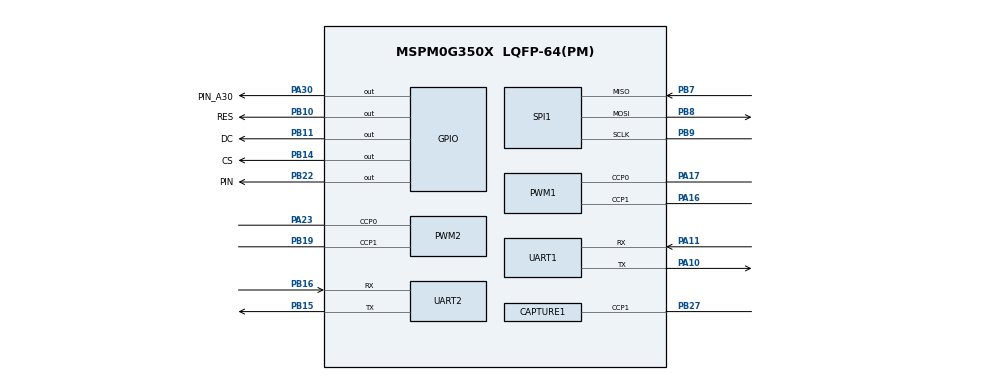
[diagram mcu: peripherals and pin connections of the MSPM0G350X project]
/**
 * @cliArgs --device "MSPM0G350X" --part "Default" --package "LQFP-64(PM)" --product "mspm0_sdk@2.05.01.01"
 * @versions {"tool":"1.21.0+3721"}
 */

/**
 * Import the modules used in this configuration.
 */
const ADC12    = scripting.addModule("/ti/driverlib/ADC12", {}, false);
const ADC121   = ADC12.addInstance();
const CAPTURE  = scripting.addModule("/ti/driverlib/CAPTURE", {}, false);
const CAPTURE1 = CAPTURE.addInstance();
const GPIO     = scripting.addModule("/ti/driverlib/GPIO", {}, false);
const GPIO1    = GPIO.addInstance();
const GPIO2    = GPIO.addInstance();
const GPIO3    = GPIO.addInstance();
const GPIO4    = GPIO.addInstance();
const GPIO5    = GPIO.addInstance();
const GPIO6    = GPIO.addInstance();
const GPIO7    = GPIO.addInstance();
const GPIO8    = GPIO.addInstance();
const GPIO9    = GPIO.addInstance();
const I2C      = scripting.addModule("/ti/driverlib/I2C", {}, false);
const I2C1     = I2C.addInstance();
const PWM      = scripting.addModule("/ti/driverlib/PWM", {}, false);
const PWM1     = PWM.addInstance();
const PWM2     = PWM.addInstance();
const SPI      = scripting.addModule("/ti/driverlib/SPI", {}, false);
const SPI1     = SPI.addInstance();
const SYSCTL   = scripting.addModule("/ti/driverlib/SYSCTL");
const SYSTICK  = scripting.addModule("/ti/driverlib/SYSTICK");
const TIMER    = scripting.addModule("/ti/driverlib/TIMER", {}, false);
const TIMER1   = TIMER.addInstance();
const TIMER2   = TIMER.addInstance();
const TIMER3   = TIMER.addInstance();
const UART     = scripting.addModule("/ti/driverlib/UART", {}, false);
const UART1    = UART.addInstance();
const UART2    = UART.addInstance();

/**
 * Write custom configuration values to the imported modules.
 */
const divider9       = system.clockTree["UDIV"];
divider9.divideValue = 2;

const mux4       = system.clockTree["EXHFMUX"];
mux4.inputSelect = "EXHFMUX_XTAL";

const mux8       = system.clockTree["HSCLKMUX"];
mux8.inputSelect = "HSCLKMUX_SYSPLL2X";

const mux12       = system.clockTree["SYSPLLMUX"];
mux12.inputSelect = "zSYSPLLMUX_HFCLK";

const pinFunction4        = system.clockTree["HFXT"];
pinFunction4.enable       = true;
pinFunction4.HFCLKMonitor = true;
pinFunction4.HFXTStartup  = 20;
pinFunction4.inputFreq    = 40;

ADC121.$name               = "ADC1";
ADC121.sampClkDiv          = "DL_ADC12_CLOCK_DIVIDE_8";
ADC121.repeatMode          = true;
ADC121.startAdd            = 4;
ADC121.adcMem4chansel      = "DL_ADC12_INPUT_CHAN_4";
ADC121.powerDownMode       = "DL_ADC12_POWER_DOWN_MODE_MANUAL";
ADC121.peripheral.$assign  = "ADC1";
ADC121.adcPin4Config.$name = "ti_driverlib_gpio_GPIOPinGeneric10";

const Board = scripting.addModule("/ti/driverlib/Board", {}, false);

CAPTURE1.$name                      = "hongwai";
CAPTURE1.captMode                   = "COMBINED_UP";
CAPTURE1.timerStartTimer            = true;
CAPTURE1.ccIndex                    = 1;
CAPTURE1.interrupts                 = ["CC0_UP","CC1_UP"];
CAPTURE1.timerPeriod                = "30ms";
CAPTURE1.timerClkPrescale           = 200;
CAPTURE1.peripheral.$assign         = "TIMG6";
CAPTURE1.peripheral.ccp1Pin.$assign = "PB27";
CAPTURE1.ccp1PinConfig.$name        = "ti_driverlib_gpio_GPIOPinGeneric7";

GPIO1.$name                          = "LED";
GPIO1.associatedPins[0].$name        = "PIN";
GPIO1.associatedPins[0].ioStructure  = "SD";
GPIO1.associatedPins[0].assignedPort = "PORTB";
GPIO1.associatedPins[0].assignedPin  = "22";
GPIO1.associatedPins[0].pin.$assign  = "PB22";

GPIO2.$name                         = "OLED";
GPIO2.port                          = "PORTB";
GPIO2.associatedPins.create(3);
GPIO2.associatedPins[0].$name       = "RES";
GPIO2.associatedPins[0].ioStructure = "SD";
GPIO2.associatedPins[0].assignedPin = "10";
GPIO2.associatedPins[0].pin.$assign = "PB10";
GPIO2.associatedPins[1].$name       = "DC";
GPIO2.associatedPins[1].ioStructure = "SD";
GPIO2.associatedPins[1].assignedPin = "11";
GPIO2.associatedPins[1].pin.$assign = "PB11";
GPIO2.associatedPins[2].$name       = "CS";
GPIO2.associatedPins[2].ioStructure = "SD";
GPIO2.associatedPins[2].assignedPin = "14";
GPIO2.associatedPins[2].pin.$assign = "PB14";

GPIO3.$name                          = "TB6612";
GPIO3.port                           = "PORTA";
GPIO3.associatedPins.create(4);
GPIO3.associatedPins[0].$name        = "AIN1";
GPIO3.associatedPins[0].initialValue = "SET";
GPIO3.associatedPins[0].assignedPin  = "14";
GPIO3.associatedPins[1].$name        = "AIN2";
GPIO3.associatedPins[1].initialValue = "SET";
GPIO3.associatedPins[1].assignedPin  = "15";
GPIO3.associatedPins[2].$name        = "BIN1";
GPIO3.associatedPins[2].initialValue = "SET";
GPIO3.associatedPins[2].assignedPin  = "12";
GPIO3.associatedPins[3].$name        = "BIN2";
GPIO3.associatedPins[3].initialValue = "SET";
GPIO3.associatedPins[3].assignedPin  = "13";

GPIO4.$name                               = "ENCODER";
GPIO4.port                                = "PORTA";
GPIO4.associatedPins.create(4);
GPIO4.associatedPins[0].$name             = "E1A";
GPIO4.associatedPins[0].direction         = "INPUT";
GPIO4.associatedPins[0].assignedPin       = "27";
GPIO4.associatedPins[0].interruptEn       = true;
GPIO4.associatedPins[0].interruptPriority = "0";
GPIO4.associatedPins[0].polarity          = "RISE";
GPIO4.associatedPins[1].$name             = "E1B";
GPIO4.associatedPins[1].direction         = "INPUT";
GPIO4.associatedPins[1].assignedPin       = "26";
GPIO4.associatedPins[1].interruptEn       = true;
GPIO4.associatedPins[1].interruptPriority = "0";
GPIO4.associatedPins[1].polarity          = "RISE";
GPIO4.associatedPins[2].$name             = "E2A";
GPIO4.associatedPins[2].direction         = "INPUT";
GPIO4.associatedPins[2].assignedPin       = "31";
GPIO4.associatedPins[2].interruptEn       = true;
GPIO4.associatedPins[2].interruptPriority = "0";
GPIO4.associatedPins[2].polarity          = "RISE";
GPIO4.associatedPins[3].$name             = "E2B";
GPIO4.associatedPins[3].direction         = "INPUT";
GPIO4.associatedPins[3].assignedPin       = "28";
GPIO4.associatedPins[3].interruptEn       = true;
GPIO4.associatedPins[3].polarity          = "RISE";
GPIO4.associatedPins[3].interruptPriority = "0";

GPIO5.$name                          = "SR04";
GPIO5.port                           = "PORTB";
GPIO5.associatedPins[0].$name        = "Trig";
GPIO5.associatedPins[0].initialValue = "SET";
GPIO5.associatedPins[0].assignedPin  = "23";

GPIO6.$name                          = "LORA";
GPIO6.associatedPins.create(2);
GPIO6.associatedPins[0].$name        = "PIN_MDO";
GPIO6.associatedPins[0].assignedPort = "PORTB";
GPIO6.associatedPins[0].assignedPin  = "26";
GPIO6.associatedPins[1].$name        = "PIN_AUX";
GPIO6.associatedPins[1].direction    = "INPUT";
GPIO6.associatedPins[1].assignedPort = "PORTA";
GPIO6.associatedPins[1].assignedPin  = "29";

GPIO7.$name                              = "KEY";
GPIO7.associatedPins.create(4);
GPIO7.associatedPins[0].$name            = "key_B25";
GPIO7.associatedPins[0].initialValue     = "SET";
GPIO7.associatedPins[0].assignedPort     = "PORTB";
GPIO7.associatedPins[0].assignedPin      = "25";
GPIO7.associatedPins[0].direction        = "INPUT";
GPIO7.associatedPins[1].$name            = "key_B24";
GPIO7.associatedPins[1].initialValue     = "SET";
GPIO7.associatedPins[1].assignedPort     = "PORTB";
GPIO7.associatedPins[1].assignedPin      = "24";
GPIO7.associatedPins[1].direction        = "INPUT";
GPIO7.associatedPins[1].internalResistor = "PULL_UP";
GPIO7.associatedPins[2].$name            = "key_A24";
GPIO7.associatedPins[2].assignedPort     = "PORTA";
GPIO7.associatedPins[2].assignedPin      = "24";
GPIO7.associatedPins[2].initialValue     = "SET";
GPIO7.associatedPins[2].direction        = "INPUT";
GPIO7.associatedPins[2].internalResistor = "PULL_UP";
GPIO7.associatedPins[3].$name            = "key_A25";
GPIO7.associatedPins[3].initialValue     = "SET";
GPIO7.associatedPins[3].assignedPort     = "PORTA";
GPIO7.associatedPins[3].assignedPin      = "25";
GPIO7.associatedPins[3].direction        = "INPUT";
GPIO7.associatedPins[3].internalResistor = "PULL_UP";

GPIO8.$name                         = "Gray_Address";
GPIO8.port                          = "PORTB";
GPIO8.associatedPins.create(3);
GPIO8.associatedPins[0].$name       = "PIN_0";
GPIO8.associatedPins[0].assignedPin = "18";
GPIO8.associatedPins[1].$name       = "PIN_1";
GPIO8.associatedPins[1].assignedPin = "0";
GPIO8.associatedPins[2].$name       = "PIN_2";
GPIO8.associatedPins[2].assignedPin = "20";

GPIO9.$name                         = "ZIsedeng";
GPIO9.port                          = "PORTA";
GPIO9.associatedPins[0].$name       = "PIN_A30";
GPIO9.associatedPins[0].assignedPin = "30";
GPIO9.associatedPins[0].pin.$assign = "PA30";

I2C1.$name                 = "I2C_0";
I2C1.basicEnableController = true;
I2C1.sdaPinConfig.$name    = "ti_driverlib_gpio_GPIOPinGeneric8";
I2C1.sclPinConfig.$name    = "ti_driverlib_gpio_GPIOPinGeneric9";

PWM1.$name                      = "PWM_0";
PWM1.timerStartTimer            = true;
PWM1.clockDivider               = 8;
PWM1.timerCount                 = 8000;
PWM1.peripheral.ccp0Pin.$assign = "PA17";
PWM1.peripheral.ccp1Pin.$assign = "PA16";
PWM1.PWM_CHANNEL_0.$name        = "ti_driverlib_pwm_PWMTimerCC0";
PWM1.PWM_CHANNEL_0.invert       = true;
PWM1.PWM_CHANNEL_1.$name        = "ti_driverlib_pwm_PWMTimerCC1";
PWM1.PWM_CHANNEL_1.invert       = true;
PWM1.ccp0PinConfig.$name        = "ti_driverlib_gpio_GPIOPinGeneric5";
PWM1.ccp1PinConfig.$name        = "ti_driverlib_gpio_GPIOPinGeneric6";

PWM2.$name                              = "PWM_Servo";
PWM2.clockDivider                       = 8;
PWM2.timerStartTimer                    = true;
PWM2.clockPrescale                      = 20;
PWM2.timerCount                         = 10000;
PWM2.peripheral.ccp0Pin.$assign         = "PA23";
PWM2.peripheral.ccp1Pin.$assign         = "PB19";
PWM2.PWM_CHANNEL_0.$name                = "ti_driverlib_pwm_PWMTimerCC2";
PWM2.PWM_CHANNEL_0.invert               = true;
PWM2.PWM_CHANNEL_1.$name                = "ti_driverlib_pwm_PWMTimerCC3";
PWM2.PWM_CHANNEL_1.invert               = true;
PWM2.ccp0PinConfig.direction            = scripting.forceWrite("OUTPUT");
PWM2.ccp0PinConfig.hideOutputInversion  = scripting.forceWrite(false);
PWM2.ccp0PinConfig.onlyInternalResistor = scripting.forceWrite(false);
PWM2.ccp0PinConfig.passedPeripheralType = scripting.forceWrite("Digital");
PWM2.ccp0PinConfig.$name                = "ti_driverlib_gpio_GPIOPinGeneric14";
PWM2.ccp1PinConfig.direction            = scripting.forceWrite("OUTPUT");
PWM2.ccp1PinConfig.hideOutputInversion  = scripting.forceWrite(false);
PWM2.ccp1PinConfig.onlyInternalResistor = scripting.forceWrite(false);
PWM2.ccp1PinConfig.passedPeripheralType = scripting.forceWrite("Digital");
PWM2.ccp1PinConfig.$name                = "ti_driverlib_gpio_GPIOPinGeneric15";

SPI1.frameFormat                        = "MOTO3";
SPI1.$name                              = "SPI_OLED";
SPI1.targetBitRate                      = 20000000;
SPI1.peripheral.$assign                 = "SPI1";
SPI1.peripheral.sclkPin.$assign         = "PB9";
SPI1.peripheral.mosiPin.$assign         = "PB8";
SPI1.peripheral.misoPin.$assign         = "PB7";
SPI1.sclkPinConfig.direction            = scripting.forceWrite("OUTPUT");
SPI1.sclkPinConfig.onlyInternalResistor = scripting.forceWrite(false);
SPI1.sclkPinConfig.passedPeripheralType = scripting.forceWrite("Digital");
SPI1.sclkPinConfig.$name                = "ti_driverlib_gpio_GPIOPinGeneric2";
SPI1.mosiPinConfig.direction            = scripting.forceWrite("OUTPUT");
SPI1.mosiPinConfig.hideOutputInversion  = scripting.forceWrite(false);
SPI1.mosiPinConfig.onlyInternalResistor = scripting.forceWrite(false);
SPI1.mosiPinConfig.passedPeripheralType = scripting.forceWrite("Digital");
SPI1.mosiPinConfig.$name                = "ti_driverlib_gpio_GPIOPinGeneric3";
SPI1.misoPinConfig.onlyInternalResistor = scripting.forceWrite(false);
SPI1.misoPinConfig.passedPeripheralType = scripting.forceWrite("Digital");
SPI1.misoPinConfig.$name                = "ti_driverlib_gpio_GPIOPinGeneric4";

SYSCTL.forceDefaultClkConfig = true;
SYSCTL.clockTreeEn           = true;
SYSCTL.validateClkStatus     = true;

SYSTICK.periodEnable  = true;
SYSTICK.period        = 80000;
SYSTICK.systickEnable = true;

TIMER1.$name              = "TIMER_0";
TIMER1.timerClkDiv        = 8;
TIMER1.timerPeriod        = "10ms";
TIMER1.timerMode          = "PERIODIC";
TIMER1.timerStartTimer    = true;
TIMER1.interrupts         = ["ZERO"];
TIMER1.interruptPriority  = "2";
TIMER1.peripheral.$assign = "TIMG0";

TIMER2.$name              = "pid";
TIMER2.timerPeriod        = "10ms";
TIMER2.timerStartTimer    = true;
TIMER2.interrupts         = ["ZERO"];
TIMER2.timerMode          = "PERIODIC";
TIMER2.timerClkPrescale   = 20;
TIMER2.timerClkDiv        = 8;
TIMER2.interruptPriority  = "0";
TIMER2.peripheral.$assign = "TIMA0";

TIMER3.$name              = "duojijishu";
TIMER3.timerPeriod        = "20ms";
TIMER3.timerClkDiv        = 8;
TIMER3.timerClkPrescale   = 200;
TIMER3.timerStartTimer    = true;
TIMER3.interrupts         = ["ZERO"];
TIMER3.peripheral.$assign = "TIMG8";

UART1.enabledInterrupts                = ["RX"];
UART1.$name                            = "MYUART";
UART1.peripheral.$assign               = "UART0";
UART1.peripheral.rxPin.$assign         = "PA11";
UART1.peripheral.txPin.$assign         = "PA10";
UART1.txPinConfig.direction            = scripting.forceWrite("OUTPUT");
UART1.txPinConfig.hideOutputInversion  = scripting.forceWrite(false);
UART1.txPinConfig.onlyInternalResistor = scripting.forceWrite(false);
UART1.txPinConfig.passedPeripheralType = scripting.forceWrite("Digital");
UART1.txPinConfig.$name                = "ti_driverlib_gpio_GPIOPinGeneric0";
UART1.txPinConfig.enableConfig         = true;
UART1.txPinConfig.internalResistor     = "PULL_UP";
UART1.rxPinConfig.hideOutputInversion  = scripting.forceWrite(false);
UART1.rxPinConfig.onlyInternalResistor = scripting.forceWrite(false);
UART1.rxPinConfig.passedPeripheralType = scripting.forceWrite("Digital");
UART1.rxPinConfig.$name                = "ti_driverlib_gpio_GPIOPinGeneric1";
UART1.rxPinConfig.enableConfig         = true;
UART1.rxPinConfig.internalResistor     = "PULL_UP";

UART2.enabledInterrupts                = ["RX"];
UART2.$name                            = "Tuoluoyi";
UART2.peripheral.$assign               = "UART2";
UART2.peripheral.rxPin.$assign         = "PB16";
UART2.peripheral.txPin.$assign         = "PB15";
UART2.txPinConfig.direction            = scripting.forceWrite("OUTPUT");
UART2.txPinConfig.hideOutputInversion  = scripting.forceWrite(false);
UART2.txPinConfig.onlyInternalResistor = scripting.forceWrite(false);
UART2.txPinConfig.passedPeripheralType = scripting.forceWrite("Digital");
UART2.txPinConfig.$name                = "ti_driverlib_gpio_GPIOPinGeneric12";
UART2.rxPinConfig.hideOutputInversion  = scripting.forceWrite(false);
UART2.rxPinConfig.onlyInternalResistor = scripting.forceWrite(false);
UART2.rxPinConfig.passedPeripheralType = scripting.forceWrite("Digital");
UART2.rxPinConfig.$name                = "ti_driverlib_gpio_GPIOPinGeneric13";

/**
 * Pinmux solution for unlocked pins/peripherals. This ensures that minor changes to the automatic solver in a future
 * version of the tool will not impact the pinmux you originally saw.  These lines can be completely deleted in order to
 * re-solve from scratch.
 */
pinFunction4.peripheral.$suggestSolution           = "SYSCTL";
pinFunction4.peripheral.hfxInPin.$suggestSolution  = "PA5";
pinFunction4.peripheral.hfxOutPin.$suggestSolution = "PA6";
ADC121.peripheral.adcPin4.$suggestSolution         = "PB17";
Board.peripheral.$suggestSolution                  = "DEBUGSS";
Board.peripheral.swclkPin.$suggestSolution         = "PA20";
Board.peripheral.swdioPin.$suggestSolution         = "PA19";
GPIO3.associatedPins[0].pin.$suggestSolution       = "PA14";
GPIO3.associatedPins[1].pin.$suggestSolution       = "PA15";
GPIO3.associatedPins[2].pin.$suggestSolution       = "PA12";
GPIO3.associatedPins[3].pin.$suggestSolution       = "PA13";
GPIO4.associatedPins[0].pin.$suggestSolution       = "PA27";
GPIO4.associatedPins[1].pin.$suggestSolution       = "PA26";
GPIO4.associatedPins[2].pin.$suggestSolution       = "PA31";
GPIO4.associatedPins[3].pin.$suggestSolution       = "PA28";
GPIO5.associatedPins[0].pin.$suggestSolution       = "PB23";
GPIO6.associatedPins[0].pin.$suggestSolution       = "PB26";
GPIO6.associatedPins[1].pin.$suggestSolution       = "PA29";
GPIO7.associatedPins[0].pin.$suggestSolution       = "PB25";
GPIO7.associatedPins[1].pin.$suggestSolution       = "PB24";
GPIO7.associatedPins[2].pin.$suggestSolution       = "PA24";
GPIO7.associatedPins[3].pin.$suggestSolution       = "PA25";
GPIO8.associatedPins[0].pin.$suggestSolution       = "PB18";
GPIO8.associatedPins[1].pin.$suggestSolution       = "PB0";
GPIO8.associatedPins[2].pin.$suggestSolution       = "PB20";
I2C1.peripheral.$suggestSolution                   = "I2C0";
I2C1.peripheral.sdaPin.$suggestSolution            = "PA0";
I2C1.peripheral.sclPin.$suggestSolution            = "PA1";
PWM1.peripheral.$suggestSolution                   = "TIMA1";
PWM2.peripheral.$suggestSolution                   = "TIMG7";
